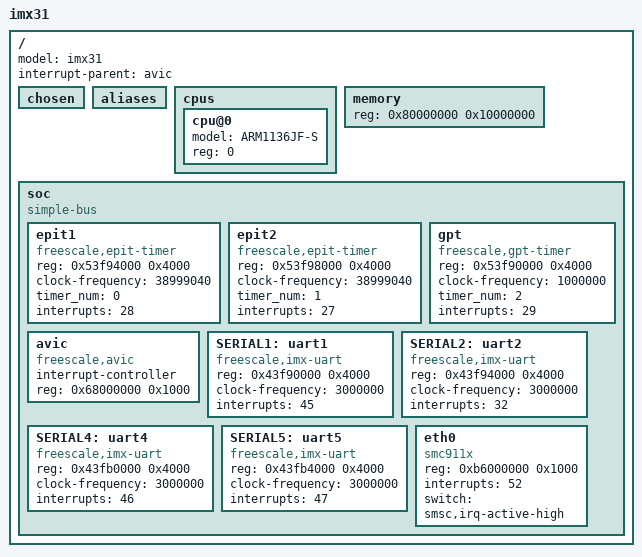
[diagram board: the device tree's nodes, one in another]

/ {
	model = "imx31";
	interrupt-parent = <&avic>;
	#address-cells = <1>;
	#size-cells = <1>;

	chosen { };
	aliases { };

	cpus {
		#address-cells = <1>;
		#size-cells = <0>;

		cpu@0 {
			device_type = "cpu";
			model = "ARM1136JF-S";
			reg = <0>;
		};
	};

	memory {
		device_type = "memory"; 
		reg = <0x80000000 0x10000000>; /* 256 MB */
	};

	soc {
		#address-cells = <1>;
		#size-cells = <1>;
		compatible = "simple-bus";

		epit1 {
			compatible = "freescale,epit-timer";
			reg = <0x53f94000 0x4000>;
			clock-frequency = <38999040>;
			timer_num = <0>;
			interrupts = <28>;
		};

		epit2 {
			compatible = "freescale,epit-timer";
			reg = <0x53f98000 0x4000>;
			clock-frequency = <38999040>;
			timer_num = <1>;
			interrupts = <27>;
		};

		gpt {
			compatible = "freescale,gpt-timer";
			reg = <0x53f90000 0x4000>;
			clock-frequency = <1000000>;
			timer_num = <2>;
			interrupts = <29>;
		};

		avic: avic {
			compatible = "freescale,avic";
			interrupt-controller;
			#interrupt-cells = <1>;
			reg = <0x68000000 0x1000>;
		};

		SERIAL1: uart1 {
	      		compatible = "freescale,imx-uart";
	      		reg = <0x43f90000 0x4000>;
			clock-frequency = <3000000>;
			interrupts = <45>;
		};

		SERIAL2: uart2 {
	      		compatible = "freescale,imx-uart";
	      		reg = <0x43f94000 0x4000>;
			clock-frequency = <3000000>;
			interrupts = <32>;
		};

		SERIAL4: uart4 {
	      		compatible = "freescale,imx-uart";
	      		reg = <0x43fb0000 0x4000>;
			clock-frequency = <3000000>;
			interrupts = <46>;
		};

		SERIAL5: uart5 {
	      		compatible = "freescale,imx-uart";
	      		reg = <0x43fb4000 0x4000>;
			clock-frequency = <3000000>;
			interrupts = <47>;
		};

		eth0 {
			compatible = "smc911x";
			reg = <0xb6000000 0x1000>;
			interrupts = <52>;
			switch = ""; /* To be set by DTS file including this file */
			smsc,irq-active-high;
		};
	};
};

